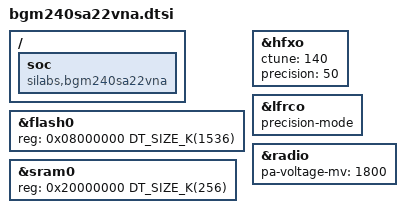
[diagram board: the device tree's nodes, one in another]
/*
 * Copyright (c) 2023 Fr. Sauter AG
 * Copyright (c) 2025 Silicon Laboratories Inc.
 * Copyright (c) 2025 Ephraim Westenberger
 *
 * SPDX-License-Identifier: Apache-2.0
 */

#include <mem.h>
#include <silabs/xg24/bgm24.dtsi>

/ {
	soc {
		compatible = "silabs,bgm240sa22vna", "silabs,bgm24", "silabs,xg24", "silabs,efr32",
			     "simple-bus";
	};
};

&flash0 {
	reg = <0x08000000 DT_SIZE_K(1536)>;
};

&hfxo {
	ctune = <140>;
	precision = <50>;
	status = "okay";
};

&lfrco {
	precision-mode;
};

&radio {
	pa-voltage-mv = <1800>;
};

&sram0 {
	reg = <0x20000000 DT_SIZE_K(256)>;
};
